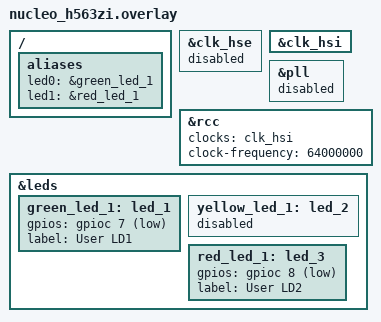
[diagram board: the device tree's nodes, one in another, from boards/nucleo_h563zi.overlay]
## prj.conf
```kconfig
# printf, printk output to RTT
CONFIG_USE_SEGGER_RTT=y
CONFIG_RTT_CONSOLE=y
CONFIG_UART_CONSOLE=n
#CONFIG_SEGGER_RTT_MODE_NO_BLOCK_TRIM=y
#CONFIG_SEGGER_RTT_BUFFER_SIZE_UP=4096
#CONFIG_SEGGER_RTT_SECTION_CUSTOM_DTS_REGION=y

#
CONFIG_GPIO=y
```

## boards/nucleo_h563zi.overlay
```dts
/ {
	aliases {
		led0 = &green_led_1;
        led1 = &red_led_1;
	};
};

&clk_hse {
	status = "disabled";
};

&clk_hsi {
	status = "okay";
};

&pll {
	status = "disabled";
};

&rcc {
	clocks = <&clk_hsi>;
	clock-frequency = <64000000>;
};

&leds {
    green_led_1: led_1 {
        gpios = <&gpioc 7 GPIO_ACTIVE_LOW>;
        label = "User LD1";
    };

	yellow_led_1: led_2 {
		status = "disabled";
	};

    red_led_1: led_3 {
        gpios = <&gpioc 8 GPIO_ACTIVE_LOW>;
        label = "User LD2";
    };
};
```

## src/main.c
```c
/*
 * Copyright (c) 2016 Intel Corporation
 *
 * SPDX-License-Identifier: Apache-2.0
 */

#include <stdio.h>
#include <zephyr/kernel.h>
#include <zephyr/drivers/gpio.h>

/* 1000 msec = 1 sec */
#define SLEEP_TIME_MS   1000

/* The devicetree node identifier for the "led0" alias. */
#define LED0_NODE DT_ALIAS(led0)
#define LED1_NODE DT_ALIAS(led1)

/*
 * A build error on this line means your board is unsupported.
 * See the sample documentation for information on how to fix this.
 */
static const struct gpio_dt_spec led = GPIO_DT_SPEC_GET(LED0_NODE, gpios);
static const struct gpio_dt_spec led1 = GPIO_DT_SPEC_GET(LED1_NODE, gpios);

int main(void)
{
	int ret;
	bool led_state = true;

	if (!gpio_is_ready_dt(&led) || !gpio_is_ready_dt(&led1)) {
		return 0;
	}

	ret = gpio_pin_configure_dt(&led, GPIO_OUTPUT_ACTIVE);
	if (ret < 0) {
		return 0;
	}

	ret = gpio_pin_configure_dt(&led1, GPIO_OUTPUT_ACTIVE);
	if (ret < 0) {
		return 0;
	}

	while (1) {
		ret = gpio_pin_toggle_dt(&led);
		if (ret < 0) {
			return 0;
		}
		ret = gpio_pin_toggle_dt(&led1);
		if (ret < 0) {
			return 0;
		}

		led_state = !led_state;
		printf("LED state: %s\n", led_state ? "ON" : "OFF");
		k_msleep(SLEEP_TIME_MS);
	}
	return 0;
}
```
